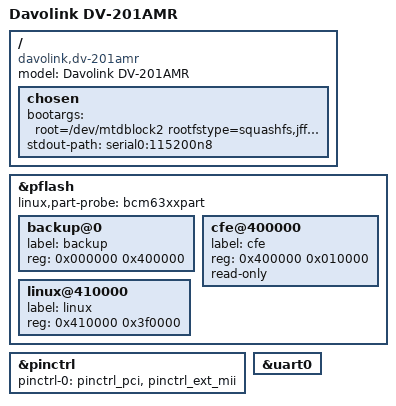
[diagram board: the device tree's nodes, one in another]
/dts-v1/;

#include "bcm6348.dtsi"

#include <dt-bindings/input/input.h>

/ {
	model = "Davolink DV-201AMR";
	compatible = "davolink,dv-201amr", "brcm,bcm6348";

	chosen {
		bootargs = "root=/dev/mtdblock2 rootfstype=squashfs,jffs2 noinitrd console=ttyS0,115200";
		stdout-path = "serial0:115200n8";
	};
};

&pflash {
	status = "ok";

	linux,part-probe = "bcm63xxpart";

	backup@0 {
		label = "backup";
		reg = <0x000000 0x400000>;
	};

	cfe@400000 {
		label = "cfe";
		reg = <0x400000 0x010000>;
		read-only;
	};

	linux@410000 {
		label = "linux";
		reg = <0x410000 0x3f0000>;
	};
};

&pinctrl {
	pinctrl-names = "default";
	pinctrl-0 = <&pinctrl_pci &pinctrl_ext_mii>;
};

&uart0 {
	status = "ok";
};
